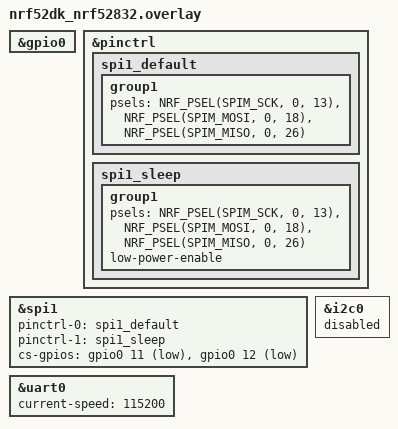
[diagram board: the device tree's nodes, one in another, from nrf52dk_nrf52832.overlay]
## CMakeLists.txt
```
# SPDX-License-Identifier: Apache-2.0

cmake_minimum_required(VERSION 3.20.0)

find_package(Zephyr REQUIRED HINTS $ENV{ZEPHYR_BASE})
project(ECG_Chestpatch)

target_sources(app PRIVATE src/main.c src/max30003.c src/lsm6dsm.c src/spi_config.c)
zephyr_library_include_directories(./include)

FILE(GLOB app_sources src/*.c)
target_sources(app PRIVATE
  ${app_sources}
  )

# zephyr_library_include_directories(${ZEPHYR_BASE}/samples/bluetooth)

# target_sources(app PRIVATE src/main.c src/max30003.c src/spi_config.c)
zephyr_library_include_directories(./include)
zephyr_library_include_directories(C:/ncs/v2.1.2/zephyr/include/) # Might only work on Vince's computer
```

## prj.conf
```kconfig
# nothing here
CONFIG_GPIO=y
CONFIG_SPI=y

CONFIG_SPI_ASYNC=y

CONFIG_SERIAL=y
CONFIG_UART_INTERRUPT_DRIVEN=y

CONFIG_SENSOR=y

CONFIG_NEWLIB_LIBC=y # Make sure to remove after debug to reduce image size?
CONFIG_NEWLIB_LIBC_FLOAT_PRINTF=y # Make sure to remove after debug to reduce image size?
# CONFIG_NEWLIB_LIBC=y # Make sure to remove after debug to reduce image size?
# CONFIG_NEWLIB_LIBC_FLOAT_PRINTF=y # Make sure to remove after debug to reduce image size?

CONFIG_BT=y
CONFIG_BT_DEBUG_LOG=y
CONFIG_BT_SMP=y
CONFIG_BT_PERIPHERAL=y
CONFIG_BT_DIS=y
CONFIG_BT_DIS_PNP=n
# CONFIG_BT_BAS=y
# CONFIG_BT_HRS=y
CONFIG_BT_DEVICE_NAME="Arthur"
CONFIG_BT_DEVICE_APPEARANCE=832
CONFIG_BT_BUF_ACL_RX_SIZE=251
CONFIG_BT_BUF_ACL_TX_SIZE=251
CONFIG_BT_L2CAP_TX_MTU=247
CONFIG_BT_CTLR_DATA_LENGTH_MAX=251
CONFIG_BT_USER_PHY_UPDATE=y
CONFIG_MAIN_STACK_SIZE=4096
```

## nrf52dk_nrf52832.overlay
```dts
// To get started, press Ctrl+Space to bring up the completion menu and view the available nodes.

// You can also use the buttons in the sidebar to perform actions on nodes.
// Actions currently available include:

// * Enabling / disabling the node
// * Adding the bus to a bus
// * Removing the node
// * Connecting ADC channels

// For more help, browse the DeviceTree documentation at https: //docs.zephyrproject.org/latest/guides/dts/index.html
// You can also visit the nRF DeviceTree extension documentation at https: //nrfconnect.github.io/vscode-nrf-connect/devicetree/nrfdevicetree.html

&gpio0 {
	status = "okay";
};

// This is where you specify which pin belongs to SCK, MOSI, and MISO. The pins need to be the same for spi1_default and spi1_sleep
&pinctrl {
	spi1_default: spi1_default {
		group1 {
			psels = <NRF_PSEL(SPIM_SCK, 0, 13)>,
				<NRF_PSEL(SPIM_MOSI, 0, 18)>,
				<NRF_PSEL(SPIM_MISO, 0, 26)>;
		};
	};

	spi1_sleep: spi1_sleep {
		group1 {
			psels = <NRF_PSEL(SPIM_SCK, 0, 13)>,
				<NRF_PSEL(SPIM_MOSI, 0, 18)>,
				<NRF_PSEL(SPIM_MISO, 0, 26)>;
			low-power-enable;
		};
	};
};


// It is CRITICAL to specify which pin belongs to cs-gpios here. Without it, the CS pins will not activate properly
&spi1 {
	status = "okay";
	pinctrl-0 = <&spi1_default>;
	pinctrl-1 = <&spi1_sleep>;
	pinctrl-names = "default", "sleep";
	cs-gpios = <&gpio0 11 GPIO_ACTIVE_LOW>,
				<&gpio0 12 GPIO_ACTIVE_LOW>;
};

&uart0 {
	current-speed = < 115200 >;
};

arduino_i2c: &i2c0 {
	status = "disabled";
};
```

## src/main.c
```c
/* main.c - Application main entry point */

/*
 * Copyright (c) 2015-2016 Intel Corporation
 *
 * SPDX-License-Identifier: Apache-2.0
 */

#include <zephyr/types.h>
#include <stddef.h>
#include <string.h>
#include <errno.h>
#include <zephyr/sys/printk.h>
#include <zephyr/sys/byteorder.h>
#include <zephyr/kernel.h>

#include <zephyr/bluetooth/bluetooth.h>
#include <zephyr/bluetooth/hci.h>
#include <zephyr/bluetooth/conn.h>
#include <zephyr/bluetooth/uuid.h>
#include <zephyr/bluetooth/gatt.h>

#include "ble_service.h"
#include "max30003.h"
#include "lsm6dsm.h"

#include <zephyr/drivers/gpio.h>

#define ECG_CHARACTERISTIC_STUFFING 30
#define ACCEL_CHARACTERISTIC_STUFFING 15 /*ENSURE IS MULTIPLE OF 3 (one for x, one for y, one for z)*/
#define GYRO_CHARACTERISTIC_STUFFING 15 /*ENSURE IS MULTIPLE OF 3 (one for x, one for y, one for z)*/

// Structure below is for setting up the Bluetooth connected LED
struct gpio_dt_spec led = 
	{
		.port = DEVICE_DT_GET(DT_NODELABEL(gpio0)),
		.pin = 20,
		.dt_flags = GPIO_ACTIVE_LOW
	};

static const struct bt_data ad[] = {
	BT_DATA_BYTES(BT_DATA_FLAGS, (BT_LE_AD_GENERAL | BT_LE_AD_NO_BREDR)),
	BT_DATA_BYTES(BT_DATA_UUID16_ALL,
		      BT_UUID_16_ENCODE(BT_UUID_DIS_VAL)),
};

// Current implementation of turning on the Bluetooth LED is weird. The board will start off with this LED on after being programmed.
static void connected(struct bt_conn *conn, uint8_t err)
{
	if (err) {
		printk("Connection failed (err 0x%02x)\n", err);
	} else {
		printk("Connected\n");
		gpio_pin_set_dt(&led, 1);
		bt_conn_le_phy_update(conn, BT_CONN_LE_PHY_PARAM_2M);
	}
}

static void disconnected(struct bt_conn *conn, uint8_t reason)
{
	printk("Disconnected (reason 0x%02x)\n", reason);
	gpio_pin_set_dt(&led, 0);
}

BT_CONN_CB_DEFINE(conn_callbacks) = {
	.connected = connected,
	.disconnected = disconnected,
};

static void bt_ready(void)
{
	int err;

	printk("Bluetooth initialized\n");

	err = bt_le_adv_start(BT_LE_ADV_CONN_NAME, ad, ARRAY_SIZE(ad), NULL, 0);
	if (err) {
		printk("Advertising failed to start (err %d)\n", err);
		return;
	}

	printk("Advertising successfully started\n");
}

static void auth_cancel(struct bt_conn *conn)
{
	char addr[BT_ADDR_LE_STR_LEN];

	bt_addr_le_to_str(bt_conn_get_dst(conn), addr, sizeof(addr));

	printk("Pairing cancelled: %s\n", addr);
}

static struct bt_conn_auth_cb auth_cb_display = {
	.cancel = auth_cancel,
};

// This function is just a wrapper for bt_ecg_notify.
static void ecg_notify(int32_t *ptr, uint8_t len)
{
	bt_ecg_notify(ptr, len);
}

// This function is just a wrapper for bt_accel_notify.
static void accel_notify(int16_t *ptr, uint8_t len)
{
	bt_accel_notify(ptr, len);
}

// This function is just a wrapper for bt_gyro_notify.
static void gyro_notify(int16_t *ptr, uint8_t len)
{
	bt_gyro_notify(ptr, len);
}

void main(void)
{
	int err;
	int ret;

	ret = gpio_pin_configure_dt(&led, GPIO_OUTPUT_ACTIVE);
	if (ret < 0) {
		return;
	}

	// Clears out any possible erroneous programming that may have occured on the peripherals
	lsm6dsm_reset_sw();
	max_reset_sw();

	lsm6dsm_enable_accel();
	lsm6dsm_enable_gyro();
	max_enable_ecg();

	err = bt_enable(NULL);
	if (err)
	{
		printk("Bluetooth init failed (err %d)\n", err);
		return;
	}

	bt_ready();

	bt_conn_auth_cb_register(&auth_cb_display);

	uint8_t lsm6dsm_status;

	int i = 0;
	int j = 0;
	int k = 0;

	int16_t accel_xyz[3] = {};
	int16_t gyro_xyz[3] = {};
	int32_t ecg_num;

	// Characteristic stuffing is when we load our data into an array and burst send it on Bluetooth. 
	// This is important as this reduces the number of times BLE has to notify and reduces the overhead associated with it.
	int32_t ecg_arr[ECG_CHARACTERISTIC_STUFFING];
	int16_t accel_arr[ACCEL_CHARACTERISTIC_STUFFING];
	int16_t gyro_arr[GYRO_CHARACTERISTIC_STUFFING];

	while (1) {
		ret = lsm6dsm_read_status(&lsm6dsm_status);
		// Checks to see if the LSM6DSM is ready to send out accelerometer data
		if (lsm6dsm_status & (1 << 0))
		{
			ret = lsm6dsm_read_accel(accel_xyz);
			if (!ret)
			{
				accel_arr[i] = accel_xyz[0];
				i += 1;
				accel_arr[i+1] = accel_xyz[1];
				i += 1;
				accel_arr[i+2] = accel_xyz[2];
				i += 1;
				if (i >= ACCEL_CHARACTERISTIC_STUFFING)
				{
					accel_notify(accel_arr, ACCEL_CHARACTERISTIC_STUFFING);
					i = 0;
				}
				// printf("Accel x: % 3.3f, y: % 3.3f, z: % 3.3f\n", ((float)accel_xyz[0]) * 0.061 / 1000 * 9.81, ((float)accel_xyz[1]) * 0.061 / 1000 * 9.81, ((float)accel_xyz[2]) * 0.061 / 1000 * 9.81);
			}
		}
		// Checks to see if the LSM6DSM is ready to send out gyroscope data
		if (lsm6dsm_status & (1 << 1))
		{
			ret = lsm6dsm_read_gyro(gyro_xyz);
			if (!ret)
			{
				gyro_arr[j] = gyro_xyz[0];
				j += 1;
				gyro_arr[j] = gyro_xyz[1];
				j += 1;
				gyro_arr[j] = gyro_xyz[2];
				j += 1;
				if (j >= GYRO_CHARACTERISTIC_STUFFING)
				{
					gyro_notify(gyro_arr, GYRO_CHARACTERISTIC_STUFFING);
					j=0;
				}
				// printf("Gyro x: % 3.3f, y: % 3.3f, z: % 3.3f\n", (gyro_xyz[0]) * 8.75 / 1000, (gyro_xyz[1]) * 8.75 / 1000, (gyro_xyz[2]) * 8.75 / 1000);
			}
		}
		ret = max_read_ecg(&ecg_num);
		if (!ret)
		{
			ecg_arr[k] = ecg_num;
			k++;
			// printk("%d\n", ecg_num);
			if (k >= ECG_CHARACTERISTIC_STUFFING)
			{
				ecg_notify(ecg_arr, ECG_CHARACTERISTIC_STUFFING);
				k = 0;
			}
		}
	}
}
```

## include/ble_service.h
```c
/*
 * Copyright (c) 2016 Intel Corporation
 *
 * SPDX-License-Identifier: Apache-2.0
 */

#ifndef ZEPHYR_INCLUDE_BLUETOOTH_SERVICES_HRS_H_
#define ZEPHYR_INCLUDE_BLUETOOTH_SERVICES_HRS_H_

/**
 * @brief Heart Rate Service (HRS)
 * @defgroup bt_hrs Heart Rate Service (HRS)
 * @ingroup bluetooth
 * @{
 *
 * [Experimental] Users should note that the APIs can change
 * as a part of ongoing development.
 */

#ifdef __cplusplus
extern "C" {
#endif

/** @brief Notify ecg measurement.
 *
 * This will send a GATT notification to all current subscribers.
 *
 *  @param ecg_val The ecg measurement as read from device.
 *
 *  @return Zero in case of success and error code in case of error.
 */
int bt_ecg_notify(int32_t *val, uint8_t len);
int bt_accel_notify(int16_t *ptr, uint8_t len);
// int bt_yaccel_notify(int16_t val);
// int bt_zaccel_notify(int16_t val);
int bt_gyro_notify(int16_t *ptr, uint8_t len);
// int bt_gyroy_notify(int16_t val);
// int bt_gyroz_notify(int16_t val);

#ifdef __cplusplus
}
#endif

/**
 * @}
 */

#endif /* ZEPHYR_INCLUDE_BLUETOOTH_SERVICES_HRS_H_ */
```

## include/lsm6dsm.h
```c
#include <stdio.h>
#include <zephyr/zephyr.h>

#ifndef LSM6DSM
#define LSM6DSM

#define BUF_SIZE 2

/*********** REGISTERS ***********/

/* Setup registers */
#define LSM6DSM_FUNC_CFG_ACCESS          (uint8_t)0x01U  /**< Enable embedded functions register (r/w) **/
#define LSM6DSM_SENSOR_SYNC_TIME_FRAME   (uint8_t)0x04U  /**< Sensor synchronization time frame register (r/w) **/
#define LSM6DSM_SENSOR_SYNC_RES_RATIO    (uint8_t)0x05U  /**< Sensor synchronization resolution ratio (r/w) **/

#define LSM6DSM_FIFO_CTRL1               (uint8_t)0x06U  /**< FIFO control register 1 (r/w) **/
#define LSM6DSM_FIFO_CTRL2               (uint8_t)0x07U  /**< FIFO control register 2 (r/w) **/
#define LSM6DSM_FIFO_CTRL3               (uint8_t)0x08U  /**< FIFO control register 3 (r/w) **/
#define LSM6DSM_FIFO_CTRL4               (uint8_t)0x09U  /**< FIFO control register 4 (r/w) **/
#define LSM6DSM_FIFO_CTRL5               (uint8_t)0x0AU  /**< FIFO control register 5 (r/w) **/

#define LSM6DSM_DRDY_PULSE_CFG_G         (uint8_t)0x0BU  /**< DataReady configuration register (r/w)**/
#define LSM6DSM_INT1_CTRL                (uint8_t)0x0DU  /**< INT1 pad control register (r/w) **/
#define LSM6DSM_INT2_CTRL                (uint8_t)0x0EU  /**< INT2 pad control register (r/w) **/

#define LSM6DSM_WHO_AM_I                 (uint8_t)0x0FU  /**< Who_AM_I register (r), value fixed at 6Ah **/

#define LSM6DSM_CTRL1_XL                 (uint8_t)0x10U  /**< Linear acceleration sensor control register 1 (r/w) **/
#define LSM6DSM_CTRL2_G                  (uint8_t)0x11U  /**< Angular rate sensor control register 2 (r/w) **/
#define LSM6DSM_CTRL3_C                  (uint8_t)0x12U  /**< Control register 3 (r/w) **/
#define LSM6DSM_CTRL4_C                  (uint8_t)0x13U  /**< Control register 4 (r/w) **/
#define LSM6DSM_CTRL5_C                  (uint8_t)0x14U  /**< Control register 5 (r/w) **/
#define LSM6DSM_CTRL6_C                  (uint8_t)0x15U  /**< Angular rate sensor control register 6 (r/w) **/
#define LSM6DSM_CTRL7_G                  (uint8_t)0x16U  /**< Angular rate sensor control register 7 (r/w) **/
#define LSM6DSM_CTRL8_XL                 (uint8_t)0x17U  /**< Linear acceleration sensor control register 8 (r/w) **/
#define LSM6DSM_CTRL9_XL                 (uint8_t)0x18U  /**< Linear acceleration sensor control register 9 (r/w) **/
#define LSM6DSM_CTRL10_C                 (uint8_t)0x19U  /**< Control register 10 (r/w) **/

#define LSM6DSM_MASTER_CONFIG            (uint8_t)0x1AU  /**< Master configuration register (r/w) **/
#define LSM6DSM_WAKE_UP_SRC              (uint8_t)0x1BU  /**< Wake up interrupt source register (r) **/
#define LSM6DSM_TAP_SRC                  (uint8_t)0x1CU  /**< Tap source register (r) **/
#define LSM6DSM_D6D_SRC                  (uint8_t)0x1DU  /**< Portrait, landscape, face-up and face-down source register (r) **/
#define LSM6DSM_STATUS_REG               (uint8_t)0x1EU  /**< Status register (r) **/


#define LSM6DSM_OUT_TEMP_L               (uint8_t)0x20U  /**< Temperature data output register Bit 7..0 (r) **/
#define LSM6DSM_OUT_TEMP_H               (uint8_t)0x21U  /**< Temperature data output register Bit 15..8 (r) **/


#define LSM6DSM_OUTX_L_G                 (uint8_t)0x22U  /**< Angular rate pitch axis X Bit 7..0 (r)**/
#define LSM6DSM_OUTX_H_G                 (uint8_t)0x23U  /**< Angular rate pitch axis X Bit 15..8 (r)**/
#define LSM6DSM_OUTY_L_G                 (uint8_t)0x24U  /**< Angular rate pitch axis Y Bit 7..0 (r)**/
#define LSM6DSM_OUTY_H_G                 (uint8_t)0x25U  /**< Angular rate pitch axis Y Bit 15..8 (r)**/
#define LSM6DSM_OUTZ_L_G                 (uint8_t)0x26U  /**< Angular rate pitch axis Z Bit 7..0 (r)**/
#define LSM6DSM_OUTZ_H_G                 (uint8_t)0x27U  /**< Angular rate pitch axis Z Bit 15..8 (r)**/

#define LSM6DSM_OUTX_L_XL                (uint8_t)0x28U  /**< Linear acceleration axis X Bit 7..0 (r)**/
#define LSM6DSM_OUTX_H_XL                (uint8_t)0x29U  /**< Linear acceleration axis X Bit 15..8 (r)**/
#define LSM6DSM_OUTY_L_XL                (uint8_t)0x2AU  /**< Linear acceleration axis Y Bit 7..0 (r)**/
#define LSM6DSM_OUTY_H_XL                (uint8_t)0x2BU  /**< Linear acceleration axis Y Bit 15..8 (r)**/
#define LSM6DSM_OUTZ_L_XL                (uint8_t)0x2CU  /**< Linear acceleration axis Z Bit 7..0 (r)**/
#define LSM6DSM_OUTZ_H_XL                (uint8_t)0x2DU  /**< Linear acceleration axis Z Bit 15..8 (r)**/

/** refer to @ref lsm6dsm_embedded_registers for following sensorhub bytes functionality **/
#define LSM6DSM_SENSORHUB1_REG           (uint8_t)0x2EU  /**< byte 1 associated to external sensors **/
#define LSM6DSM_SENSORHUB2_REG           (uint8_t)0x2FU  /**< byte 2 associated to external sensors **/
#define LSM6DSM_SENSORHUB3_REG           (uint8_t)0x30U  /**< byte 3 associated to external sensors **/
#define LSM6DSM_SENSORHUB4_REG           (uint8_t)0x31U  /**< byte 4 associated to external sensors **/
#define LSM6DSM_SENSORHUB5_REG           (uint8_t)0x32U  /**< byte 5 associated to external sensors **/
#define LSM6DSM_SENSORHUB6_REG           (uint8_t)0x33U  /**< byte 6 associated to external sensors **/
#define LSM6DSM_SENSORHUB7_REG           (uint8_t)0x34U  /**< byte 7 associated to external sensors **/
#define LSM6DSM_SENSORHUB8_REG           (uint8_t)0x35U  /**< byte 8 associated to external sensors **/
#define LSM6DSM_SENSORHUB9_REG           (uint8_t)0x36U  /**< byte 9 associated to external sensors **/
#define LSM6DSM_SENSORHUB10_REG          (uint8_t)0x37U  /**< byte 10 associated to external sensors **/
#define LSM6DSM_SENSORHUB11_REG          (uint8_t)0x38U  /**< byte 11 associated to external sensors **/ 
#define LSM6DSM_SENSORHUB12_REG          (uint8_t)0x39U  /**< byte 12 associated to external sensors **/

/** For a proper reading of the following registers, 
 *  it is recommended to set the BDU bit in CTRL3_C (12h) to 1 **/
#define LSM6DSM_FIFO_STATUS1             (uint8_t)0x3AU  /**< FIFO status control 1 (r) **/
#define LSM6DSM_FIFO_STATUS2             (uint8_t)0x3BU  /**< FIFO status control 2 (r)**/
#define LSM6DSM_FIFO_STATUS3             (uint8_t)0x3CU  /**< FIFO status control 3 (r)**/
#define LSM6DSM_FIFO_STATUS4             (uint8_t)0x3DU  /**< FIFO status control 4 (r) **/

#define LSM6DSM_FIFO_DATA_OUT_L          (uint8_t)0x3EU  /**< FIFO data output - Bit 7..0 (r)**/
#define LSM6DSM_FIFO_DATA_OUT_H          (uint8_t)0x3FU  /**< FIFO data output Bit - 15..8 (r)**/

/** to reset the Timestamp timer, (uint8_t)0xAA has to be written in TIMESTAMP2_REG **/
#define LSM6DSM_TIMESTAMP0_REG           (uint8_t)0x40U  /**< Timestamp data output - Bit 7..0 (r) **/
#define LSM6DSM_TIMESTAMP1_REG           (uint8_t)0x41U  /**< Timestamp data output - Bit 15..8 (r) **/
#define LSM6DSM_TIMESTAMP2_REG           (uint8_t)0x42U  /**< Timestamp data output - Bit 23..16 (r/w) **/
#define LSM6DSM_STEP_TIMESTAMP_L         (uint8_t)0x49U  /**< Step counter timestamp - contains TIMESTAMP0 (r)**/
#define LSM6DSM_STEP_TIMESTAMP_H         (uint8_t)0x4AU  /**< Step counter timestamp - contains TIMESTAMP1 (r)**/
#define LSM6DSM_STEP_COUNTER_L           (uint8_t)0x4BU  /**< Step counter output register - Bit 7..0 (r) **/
#define LSM6DSM_STEP_COUNTER_H           (uint8_t)0x4CU  /**< Step counter output register - Bit 13..8 (r) **/

#define LSM6DSM_SENSORHUB13_REG          (uint8_t)0x4DU  /**< byte 13 associated to external sensors **/
#define LSM6DSM_SENSORHUB14_REG          (uint8_t)0x4EU  /**< byte 14 associated to external sensors **/
#define LSM6DSM_SENSORHUB15_REG          (uint8_t)0x4FU  /**< byte 15 associated to external sensors **/
#define LSM6DSM_SENSORHUB16_REG          (uint8_t)0x50U  /**< byte 16 associated to external sensors **/
#define LSM6DSM_SENSORHUB17_REG          (uint8_t)0x51U  /**< byte 17 associated to external sensors **/
#define LSM6DSM_SENSORHUB18_REG          (uint8_t)0x52U  /**< byte 18 associated to external sensors **/
  
#define LSM6DSM_FUNC_SRC1                (uint8_t)0x53U  /**< Significant motion, tilt, step detector,   **/ 
                                                    /** hard/soft-iron and sensor hub interrupt source (r) **/
#define LSM6DSM_FUNC_SRC2                (uint8_t)0x54U  /**< Wrist tilt and slave NAK interrupt source (r) **/

#define LSM6DSM_WRIST_TILT_IA            (uint8_t)0x55U  /**< Wrist tilt interrupt source (r) **/
#define LSM6DSM_TAP_CFG                  (uint8_t)0x58U  /**< interrupt, inactivity function , filtering (r/w) **/
#define LSM6DSM_TAP_THS_6D               (uint8_t)0x59U  /**< Portrait/landscape, tap function threshold (r/w) **/
#define LSM6DSM_INT_DUR2                 (uint8_t)0x5AU  /**< Tap recognition function setting (r/w) **/
#define LSM6DSM_WAKE_UP_THS              (uint8_t)0x5BU  /**< Single and double-tap function threshold (r/w) **/
#define LSM6DSM_WAKE_UP_DUR              (uint8_t)0x5CU  /**< Free-fall, wakeup, timestamp, sleep duration (r/w) **/
#define LSM6DSM_FREE_FALL                (uint8_t)0x5DU  /**< Free-fall function duration setting register (r/w) **/
#define LSM6DSM_MD1_CFG                  (uint8_t)0x5EU  /**< Functions routing on INT1 register (r/w) **/
#define LSM6DSM_MD2_CFG                  (uint8_t)0x5FU  /**< Functions routing on INT2 register (r/w) **/

#define LSM6DSM_MASTER_CMD_CODE          (uint8_t)0x60U  /**< Master command code used for stamping **/
#define LSM6DSM_SENS_SYNC_SPI_ERROR_CODE (uint8_t)0x61U  /**< Error code used for sensor synchronization **/

#define LSM6DSM_OUT_MAG_RAW_X_L          (uint8_t)0x66U  /**< External magnetometer X data - Bit 7..0 (r) **/
#define LSM6DSM_OUT_MAG_RAW_X_H          (uint8_t)0x67U  /**< External magnetometer X data - Bit 15..8 (r) **/
#define LSM6DSM_OUT_MAG_RAW_Y_L          (uint8_t)0x68U  /**< External magnetometer Y data - Bit 7..0 (r) **/
#define LSM6DSM_OUT_MAG_RAW_Y_H          (uint8_t)0x69U  /**< External magnetometer Y data - Bit 15..8 (r) **/
#define LSM6DSM_OUT_MAG_RAW_Z_L          (uint8_t)0x6AU  /**< External magnetometer Z data - Bit 7..0 (r) **/
#define LSM6DSM_OUT_MAG_RAW_Z_H          (uint8_t)0x6BU  /**< External magnetometer Z data - Bit 15..8 (r) **/

#define LSM6DSM_INT_OIS                  (uint8_t)0x6FU  /**< OIS interrupt config (r) (AUX SPI (r/w)) **/
#define LSM6DSM_CTRL1_OIS                (uint8_t)0x70U  /**< OIS configuration 1 (r) (AUX SPI (r/w)) **/
#define LSM6DSM_CTRL2_OIS                (uint8_t)0x71U  /**< OIS configuration 2 (r) (AUX SPI (r/w)) **/
#define LSM6DSM_CTRL3_OIS                (uint8_t)0x72U  /**< OIS configuration 3 (r) (AUX SPI (r/w)) **/

#define LSM6DSM_X_OFS_USR                (uint8_t)0x73U  /**< Accelerometer X user offset correction (r/w) **/
#define LSM6DSM_Y_OFS_USR                (uint8_t)0x74U  /**< Accelerometer Y user offset correction (r/w) **/
#define LSM6DSM_Z_OFS_USR                (uint8_t)0x75U  /**< Accelerometer Z user offset correction (r/w) **/
/*! @} */

/*! @defgroup lsm6dsm_embedded_registers Group: embedded registers   
*  lsm6dsm embedded registers
*  @{
*/
#define LSM6DSM_SLV0_ADD                 (uint8_t)0x02U /**< I2C slave address Sensor   1 (r/w) **/
#define LSM6DSM_SLV0_SUBADD              (uint8_t)0x03U /**< Address of register Sensor 1 (r/w) **/
#define LSM6DSM_SLAVE0_CONFIG            (uint8_t)0x04U /**< configuration Sensor 1, sensor hub (r/w) **/
#define LSM6DSM_SLV1_ADD                 (uint8_t)0x05U /**< I2C slave address Sensor   2 (r/w) **/
#define LSM6DSM_SLV1_SUBADD              (uint8_t)0x06U /**< Address of register Sensor 2 (r/w) **/
#define LSM6DSM_SLAVE1_CONFIG            (uint8_t)0x07U /**< configuration Sensor       2 (r/w) **/
#define LSM6DSM_SLV2_ADD                 (uint8_t)0x08U /**< I2C slave address Sensor   3 (r/w) **/
#define LSM6DSM_SLV2_SUBADD              (uint8_t)0x09U /**< Address of register Sensor 3 (r/w) **/
#define LSM6DSM_SLAVE2_CONFIG            (uint8_t)0x0AU /**< configuration Sensor       3 (r/w) **/
#define LSM6DSM_SLV3_ADD                 (uint8_t)0x0BU /**< I2C slave address Sensor   4 (r/w) **/
#define LSM6DSM_SLV3_SUBADD              (uint8_t)0x0CU /**< Address of register Sensor 4 (r/w) **/
#define LSM6DSM_SLAVE3_CONFIG            (uint8_t)0x0DU /**< configuration Sensor       4 (r/w) **/

#define LSM6DSM_DATAWR_SRC_MODE_SUB_SLV0 (uint8_t)0x0EU /**< Write in SLV0 register  (r/w) **/
#define LSM6DSM_CONFIG_PEDO_THS_MIN      (uint8_t)0x0FU /**< Pedometer configuration (r/w) **/

#define LSM6DSM_SM_THS                   (uint8_t)0x13U /**< Significant motion configuration (r/w) **/
#define LSM6DSM_PEDO_DEB_REG             (uint8_t)0x14U /**< Pedometer debounce configuration (r/w) **/
#define LSM6DSM_STEP_COUNT_DELTA         (uint8_t)0x15U /**< Time period step detection  (r/w) **/

#define LSM6DSM_MAG_SI_XX                (uint8_t)0x24U /**< Soft-iron matrix correction row,col 1,1 (r/w)  **/
#define LSM6DSM_MAG_SI_XY                (uint8_t)0x25U /**< Soft-iron matrix correction row,col 1,2 (r/w)  **/
#define LSM6DSM_MAG_SI_XZ                (uint8_t)0x26U /**< Soft-iron matrix correction row,col 1,3 (r/w)  **/
#define LSM6DSM_MAG_SI_YX                (uint8_t)0x27U /**< Soft-iron matrix correction row,col 2,1 (r/w)  **/
#define LSM6DSM_MAG_SI_YY                (uint8_t)0x28U /**< Soft-iron matrix correction row,col 2,2 (r/w)  **/
#define LSM6DSM_MAG_SI_YZ                (uint8_t)0x29U /**< Soft-iron matrix correction row,col 2,3 (r/w)  **/
#define LSM6DSM_MAG_SI_ZX                (uint8_t)0x2AU /**< Soft-iron matrix correction row,col 3,1 (r/w)  **/
#define LSM6DSM_MAG_SI_ZY                (uint8_t)0x2BU /**< Soft-iron matrix correction row,col 3,2 (r/w)  **/
#define LSM6DSM_MAG_SI_ZZ                (uint8_t)0x2CU /**< Soft-iron matrix correction row,col 3,3 (r/w)  **/

#define LSM6DSM_MAG_OFFX_L               (uint8_t)0x2DU /**< Offset X-axis hard-iron compensation Bit 7..0 (r/w)**/
#define LSM6DSM_MAG_OFFX_H               (uint8_t)0x2EU /**< Offset X-axis hard-iron compensation Bit 15..8 (r/w)**/
#define LSM6DSM_MAG_OFFY_L               (uint8_t)0x2FU /**< Offset Y-axis hard-iron compensation Bit 7..0 (r/w)**/
#define LSM6DSM_MAG_OFFY_H               (uint8_t)0x30U /**< Offset Y-axis hard-iron compensation Bit 15..8 (r/w)**/
#define LSM6DSM_MAG_OFFZ_L               (uint8_t)0x31U /**< Offset Z-axis hard-iron compensation Bit 7..0 (r/w)**/
#define LSM6DSM_MAG_OFFZ_H               (uint8_t)0x32U /**< Offset Z-axis hard-iron compensation Bit 15..8 (r/w)**/

#define LSM6DSM_A_WRIST_TILT_LAT         (uint8_t)0x50U /**< Absolute Wrist Tilt latency (r/w) **/
#define LSM6DSM_A_WRIST_TILT_THS         (uint8_t)0x54U /**< Absolute Wrist Tilt threshold (r/w)**/
#define LSM6DSM_A_WRIST_TILT_MASK        (uint8_t)0x59U /**< Absolute Wrist Tilt mask (r/w)**/

/*! @} */

/*********** FUNCTIONS ***********/

bool lsm6dsm_read_who_am_i();

int lsm6dsm_enable_accel();
int lsm6dsm_write_buffer(uint8_t reg, uint8_t data);
int lsm6dsm_read_buffer(uint8_t reg, uint8_t *out_data);
int lsm6dsm_read_status(uint8_t *status_data);
int lsm6dsm_read_accel(int16_t *out_xyz);
int lsm6dsm_read_gyro(int16_t *out_xyz);

#endif // LSM6DSM
```

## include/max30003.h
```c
/*******************************************************************************
 * Copyright (C) 2017 Maxim Integrated Products, Inc., All Rights Reserved.
 *
 * Permission is hereby granted, free of charge, to any person obtaining a
 * copy of this software and associated documentation files (the "Software"),
 * to deal in the Software without restriction, including without limitation
 * the rights to use, copy, modify, merge, publish, distribute, sublicense,
 * and/or sell copies of the Software, and to permit persons to whom the
 * Software is furnished to do so, subject to the following conditions:
 *
 * The above copyright notice and this permission notice shall be included
 * in all copies or substantial portions of the Software.
 *
 * THE SOFTWARE IS PROVIDED "AS IS", WITHOUT WARRANTY OF ANY KIND, EXPRESS
 * OR IMPLIED, INCLUDING BUT NOT LIMITED TO THE WARRANTIES OF
 * MERCHANTABILITY, FITNESS FOR A PARTICULAR PURPOSE AND NONINFRINGEMENT.
 * IN NO EVENT SHALL MAXIM INTEGRATED BE LIABLE FOR ANY CLAIM, DAMAGES
 * OR OTHER LIABILITY, WHETHER IN AN ACTION OF CONTRACT, TORT OR OTHERWISE,
 * ARISING FROM, OUT OF OR IN CONNECTION WITH THE SOFTWARE OR THE USE OR
 * OTHER DEALINGS IN THE SOFTWARE.
 *
 * Except as contained in this notice, the name of Maxim Integrated
 * Products, Inc. shall not be used except as stated in the Maxim Integrated
 * Products, Inc. Branding Policy.
 *
 * The mere transfer of this software does not imply any licenses
 * of trade secrets, proprietary technology, copyrights, patents,
 * trademarks, maskwork rights, or any other form of intellectual
 * property whatsoever. Maxim Integrated Products, Inc. retains all
 * ownership rights.
 *******************************************************************************
 */

#ifndef _MAX30003_H_
#define _MAX30003_H_

// #include "mbed.h"
#include <string.h>
#include <stdio.h>
#include <zephyr/zephyr.h>

#include "spi_config.h"

#define MAX_BUF_SIZE 4

/**
 * @brief Library for MAX30003\n
 * The MAX30003 is a complete, biopotential, analog frontend solution for
 * wearable applications. It offers high performance for clinical and fitness
 * applications, with ultra-low power for long battery life. The MAX30003 is a
 * single biopotential channel providing ECG waveforms and heart rate detection.
 *
 * @code
 * #include "mbed.h"
 * #include "max32630fthr.h"
 * #include "MAX30003.h"
 *
 * MAX32630FTHR pegasus(MAX32630FTHR::VIO_3V3);
 *
 * int main(void)
 * {
 *     DigitalOut rLed(LED1, 1);
 *     DigitalOut gLed(LED2, 1);
 *
 *     Serial pc(USBTX, USBRX);
 *     pc.baud(115200);
 *
 *     SPI spiBus(SPI2_MOSI, SPI2_MISO, SPI2_SCK);
 *     MAX30003 ecgAfe(spiBus, P5_3);
 *
 *     while(1)
 *     {
 *         gLed = !gLed;
 *         wait(0.1);
 *     }
 * }
 * @endcode
 */

enum Registers_e
{
    NO_OP = 0x00,
    STATUS = 0x01,
    EN_INT = 0x02,
    EN_INT2 = 0x03,
    MNGR_INT = 0x04,
    MNGR_DYN = 0x05,
    SW_RST = 0x08,
    SYNCH = 0x09,
    FIFO_RST = 0x0A,
    INFO = 0x0F,
    CNFG_GEN = 0x10,
    CNFG_ALL = 0x12,
    CNFG_EMUX = 0x14,
    CNFG_ECG = 0x15,
    CNFG_RTOR1 = 0x1D,
    CNFG_RTOR2 = 0x1E,
    ECG_FIFO_BURST = 0x20,
    ECG_FIFO = 0x21,
    RTOR = 0x25,
    NO_OP2 = 0x7F
};

#define STATUS_LOFF_NL 0
#define STATUS_LOFF_NH 1
#define STATUS_LOFF_PL 2
#define STATUS_LOFF_PH 3
#define STATUS_PLLINT 8
#define STATUS_SAMP 9
#define STATUS_RRINT 10
#define STATUS_LONINT 11
#define STATUS_DCLOFFINT 20
#define STATUS_FSTINT 21
#define STATUS_EOVF 22
#define STATUS_EINT 23

#define EN_INT_INTB_TYPE 0
#define EN_INT_EN_PLLINT 8
#define EN_INT_EN_SAMP 9
#define EN_INT_EN_RRINT 10
#define EN_INT_EN_LONINT 11
#define EN_INT_EN_DCL_OFFINT 20
#define EN_INT_EN_FSTINT 21
#define EN_INT_EN_EOVF 22
#define EN_INT_EN_EINT 23

#define MNGR_INT_SAMP_IT 0
#define MNGR_INT_CLR_SAMP 2
#define MNGR_INT_CLR_RRINT 4
#define MNGR_INT_CLR_FAST 6
#define MNGR_INT_EFIT 19

#define MNGR_DYN_FAST_TH 16
#define MNGR_DYN_FAST 22

#define CNFG_GEN_RBIASN 0
#define CNFG_GEN_RBIASP 1
#define CNFG_GEN_RBIASV 2
#define CNFG_GEN_EN_RBIAS 4
#define CNFG_GEN_VTH 6
#define CNFG_GEN_IMAG 8
#define CNFG_GEN_IPOL 3
#define CNFG_GEN_EN_DCLOFF 12
#define CNFG_GEN_EN_ECG 19
#define CNFG_GEN_FMSTR 20
#define CNFG_GEN_EN_ULP_LON 22

#define CNFG_CAL_THIGH 0
#define CNFG_CAL_FIFTY 11
#define CNFG_CAL_FCAL 12
#define CNFG_CAL_VMAG 20
#define CNFG_CAL_VMODE 21
#define CNFG_CAL_EN_VCAL 22

#define CNFG_EMUX_CALN_SEL 16
#define CNFG_EMUX_CALP_SEL 18
#define CNFG_EMUX_OPENN 20
#define CNFG_EMUX_OPENP 21
#define CNFG_EMUX_POL 23

#define CNFG_ECG_DLPF 12
#define CNFG_ECG_DHPF 14
#define CNFG_ECG_GAIN 16
#define CNFG_ECG_RATE 22

#define CNFG_RTOR1_PTSF 8
#define CNFG_RTOR1_PAVG 12
#define CNFG_RTOR1_EN_RTOR 15
#define CNFG_RTOR1_GAIN 16
#define CNFG_RTOR1_WNDW 20

#define CNFG_RTOR2_RHSF 8
#define CNFG_RTOR2_RAVG 12
#define CNFG_RTOR2_HOFF 16

bool max_readinfo(void);

bool max_reset_sw(void);

int max_enable_ecg(void);

int max_readstatus(void);

int max_read_ecg(int32_t *out_val);

int max30003_write(uint8_t reg, void *data, size_t size);

int max30003_write_uint32(uint8_t reg, uint32_t data);

int max30003_read(uint8_t reg, void *data, size_t size);

#endif /* _MAX30003_H_ */
```

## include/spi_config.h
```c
#ifndef SPI_CONFIG
#define SPI_CONFIG

#include <zephyr/drivers/spi.h>

// CONFIGURATION STRUCTURES
extern struct spi_cs_control max_spi_cs;
extern struct spi_cs_control accel_spi_cs;

extern struct spi_config max_spi_cfg;
extern struct spi_config accel_spi_cfg;

// DEVICE POINTER
extern const struct device *spi_device;

#endif //SPI_CONFIG
```

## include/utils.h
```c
#ifndef UTILS
#define UTILS

#include <string.h>
#include <stdio.h>
#include <zephyr/zephyr.h>

static inline void to_display_format(const uint8_t *src, size_t size, char *dst)
{
	size_t i;

	for (i = 0; i < size; i++)
	{
		sprintf(dst + 5 * i, "0x%02x,", src[i]);
	}
}

#endif //UTILS
```

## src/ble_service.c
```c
/** @file
 *  @brief HRS Service sample
 */

/*
 * Copyright (c) 2016 Intel Corporation
 *
 * SPDX-License-Identifier: Apache-2.0
 */

#include <zephyr/types.h>
#include <stddef.h>
#include <string.h>
#include <errno.h>
#include <zephyr/zephyr.h>
#include <zephyr/init.h>

#include <zephyr/bluetooth/bluetooth.h>
#include <zephyr/bluetooth/hci.h>
#include <zephyr/bluetooth/conn.h>
#include <zephyr/bluetooth/uuid.h>
#include <zephyr/bluetooth/gatt.h>

#define LOG_LEVEL CONFIG_BT_HRS_LOG_LEVEL
#include <zephyr/logging/log.h>
LOG_MODULE_REGISTER(ecg);


#define GATT_PERM_READ_MASK     (BT_GATT_PERM_READ | \
				 BT_GATT_PERM_READ_ENCRYPT | \
				 BT_GATT_PERM_READ_AUTHEN)
#define GATT_PERM_WRITE_MASK    (BT_GATT_PERM_WRITE | \
				 BT_GATT_PERM_WRITE_ENCRYPT | \
				 BT_GATT_PERM_WRITE_AUTHEN)

#ifndef CONFIG_BT_HRS_DEFAULT_PERM_RW_AUTHEN
#define CONFIG_BT_HRS_DEFAULT_PERM_RW_AUTHEN 0
#endif
#ifndef CONFIG_BT_HRS_DEFAULT_PERM_RW_ENCRYPT
#define CONFIG_BT_HRS_DEFAULT_PERM_RW_ENCRYPT 0
#endif
#ifndef CONFIG_BT_HRS_DEFAULT_PERM_RW
#define CONFIG_BT_HRS_DEFAULT_PERM_RW 0
#endif

#define HRS_GATT_PERM_DEFAULT (						\
	CONFIG_BT_HRS_DEFAULT_PERM_RW_AUTHEN ?				\
	(BT_GATT_PERM_READ_AUTHEN | BT_GATT_PERM_WRITE_AUTHEN) :	\
	CONFIG_BT_HRS_DEFAULT_PERM_RW_ENCRYPT ?				\
	(BT_GATT_PERM_READ_ENCRYPT | BT_GATT_PERM_WRITE_ENCRYPT) :	\
	(BT_GATT_PERM_READ | BT_GATT_PERM_WRITE))			\

// Custom service UUID
#define BT_UUID_ECG_SERVICE_VAL BT_UUID_128_ENCODE(0xed6c43b9, 0xb481, 0x4735, 0xad3a, 0x182d050c3688) //ed6c43b9-b481-4735-ad3a-182d050c3688
#define BT_UUID_ECG_SERVICE BT_UUID_DECLARE_128(BT_UUID_ECG_SERVICE_VAL)

// Custom ECG characteristic UUID
#define BT_ECG_CHRC_VAL BT_UUID_128_ENCODE(0x60a19d0d, 0x7e6c, 0x4d6a, 0xac49, 0x9b3c29a0ca94) //60a19d0d-7e6c-4d6a-ac49-9b3c29a0ca94
#define BT_ECG_CHRC BT_UUID_DECLARE_128(BT_ECG_CHRC_VAL)

// Custom accelerometer service UUID
#define BT_UUID_ACCELEROMETER_SERVICE_VAL1 BT_UUID_128_ENCODE(0xb35a0ebb, 0x4f41, 0x41b0, 0x8d70, 0x96b4dc15d9e7) //b35a0ebb-4f41-41b0-8d70-96b4dc15d9e7
#define BT_UUID_ACCELEROMETER_SERVICE1 BT_UUID_DECLARE_128(BT_UUID_ACCELEROMETER_SERVICE_VAL1)

// Custom accelerometer x characteristic UUID
#define BT_XACCEL_CHRC_VAL BT_UUID_128_ENCODE(0x3b8cdf21, 0x24a2, 0x468c, 0x9236, 0x20f50b770bf5) //3b8cdf21-24a2-468c-9236-20f50b770bf5
#define BT_XACCEL_CHRC BT_UUID_DECLARE_128(BT_XACCEL_CHRC_VAL)

// Custom accelerometer y characteristic UUID
#define BT_YACCEL_CHRC_VAL BT_UUID_128_ENCODE(0x1094b4ef, 0x76bd, 0x4341, 0xaa96, 0x83f99198db63) //1094b4ef-76bd-4341-aa96-83f99198db63
#define BT_YACCEL_CHRC BT_UUID_DECLARE_128(BT_YACCEL_CHRC_VAL)

// Custom accelerometer z characteristic UUID
#define BT_ZACCEL_CHRC_VAL BT_UUID_128_ENCODE(0xf5f4e4fe, 0x1ab0, 0x4aea, 0x9334, 0xb19fc27d6e7c) //f5f4e4fe-1ab0-4aea-9334-b19fc27d6e7c
#define BT_ZACCEL_CHRC BT_UUID_DECLARE_128(BT_ZACCEL_CHRC_VAL)

// Custom accelerometer gyro characteristic UUID
#define BT_GYRO_CHRC_VAL BT_UUID_128_ENCODE(0xff3675ff, 0x5479, 0x4e1c, 0x9d87, 0xa0ac6e2dadbf) //ff3675ff-5479-4e1c-9d87-a0ac6e2dadbf
#define BT_GYRO_CHRC BT_UUID_DECLARE_128(BT_GYRO_CHRC_VAL)

#define BT_GYROY_CHRC_VAL BT_UUID_128_ENCODE(0xc040eb24, 0x7174, 0x4f86, 0xa547, 0x659b538d9c31) // c040eb24-7174-4f86-a547-659b538d9c31
#define BT_GYROY_CHRC BT_UUID_DECLARE_128(BT_GYROY_CHRC_VAL)

#define BT_GYROZ_CHRC_VAL BT_UUID_128_ENCODE(0x4f30dd9e, 0x9c7c, 0x48d5, 0xb071, 0xd1924af65ac6) // 4f30dd9e-9c7c-48d5-b071-d1924af65ac6
#define BT_GYROZ_CHRC BT_UUID_DECLARE_128(BT_GYROZ_CHRC_VAL)

static int32_t ecg_reading;
static int16_t accelx_reading;
static int16_t accely_reading;
static int16_t accelz_reading;
static int16_t gyro_reading;
static int16_t gyroy_reading;
static int16_t gyroz_reading;

static void ecg_ccc_cfg_changed(const struct bt_gatt_attr *attr, int16_t value)
{
	ARG_UNUSED(attr);

	bool notif_enabled = (value == BT_GATT_CCC_NOTIFY);

	LOG_INF("notifications %s", notif_enabled ? "enabled" : "disabled");
}

static void xaccel_ccc_cfg_changed(const struct bt_gatt_attr *attr, int16_t value)
{
	ARG_UNUSED(attr);

	bool notif_enabled = (value == BT_GATT_CCC_NOTIFY);

	LOG_INF("notifications %s", notif_enabled ? "enabled" : "disabled");
}

static void yaccel_ccc_cfg_changed(const struct bt_gatt_attr *attr, int16_t value)
{
	ARG_UNUSED(attr);

	bool notif_enabled = (value == BT_GATT_CCC_NOTIFY);

	LOG_INF("notifications %s", notif_enabled ? "enabled" : "disabled");
}

static void zaccel_ccc_cfg_changed(const struct bt_gatt_attr *attr, int16_t value)
{
	ARG_UNUSED(attr);

	bool notif_enabled = (value == BT_GATT_CCC_NOTIFY);

	LOG_INF("notifications %s", notif_enabled ? "enabled" : "disabled");
}

static void gyro_ccc_cfg_changed(const struct bt_gatt_attr *attr, int16_t value)
{
	ARG_UNUSED(attr);

	bool notif_enabled = (value == BT_GATT_CCC_NOTIFY);

	LOG_INF("notifications %s", notif_enabled ? "enabled" : "disabled");
}

static void gyroy_ccc_cfg_changed(const struct bt_gatt_attr *attr, int16_t value)
{
	ARG_UNUSED(attr);

	bool notif_enabled = (value == BT_GATT_CCC_NOTIFY);

	LOG_INF("notifications %s", notif_enabled ? "enabled" : "disabled");
}

static void gyroz_ccc_cfg_changed(const struct bt_gatt_attr *attr, int16_t value)
{
	ARG_UNUSED(attr);

	bool notif_enabled = (value == BT_GATT_CCC_NOTIFY);

	LOG_INF("notifications %s", notif_enabled ? "enabled" : "disabled");
}


/* ECG Service Declaration */
BT_GATT_SERVICE_DEFINE(ecg_svc,
	BT_GATT_PRIMARY_SERVICE(BT_UUID_ECG_SERVICE),
	BT_GATT_CHARACTERISTIC(BT_ECG_CHRC, BT_GATT_CHRC_NOTIFY,
			       BT_GATT_PERM_NONE, NULL, NULL, NULL),
	BT_GATT_CCC(ecg_ccc_cfg_changed,
		    HRS_GATT_PERM_DEFAULT),
);

/* Accelerometer Service Declaration */
BT_GATT_SERVICE_DEFINE(accelerometer_svc,
	BT_GATT_PRIMARY_SERVICE(BT_UUID_ACCELEROMETER_SERVICE1),
	BT_GATT_CHARACTERISTIC(BT_XACCEL_CHRC, BT_GATT_CHRC_NOTIFY,
			       BT_GATT_PERM_NONE, NULL, NULL, NULL),
	BT_GATT_CCC(xaccel_ccc_cfg_changed,
		    HRS_GATT_PERM_DEFAULT),
	BT_GATT_CHARACTERISTIC(BT_YACCEL_CHRC, BT_GATT_CHRC_NOTIFY,
			       BT_GATT_PERM_NONE, NULL, NULL, NULL),
	BT_GATT_CCC(yaccel_ccc_cfg_changed,
		    HRS_GATT_PERM_DEFAULT),
	BT_GATT_CHARACTERISTIC(BT_ZACCEL_CHRC, BT_GATT_CHRC_NOTIFY,
				BT_GATT_PERM_NONE, NULL, NULL, NULL),
	BT_GATT_CCC(zaccel_ccc_cfg_changed,
		    HRS_GATT_PERM_DEFAULT),
	BT_GATT_CHARACTERISTIC(BT_GYRO_CHRC, BT_GATT_CHRC_NOTIFY,
				BT_GATT_PERM_NONE, NULL, NULL, NULL),
	BT_GATT_CCC(gyro_ccc_cfg_changed,
		    HRS_GATT_PERM_DEFAULT),
	BT_GATT_CHARACTERISTIC(BT_GYROY_CHRC, BT_GATT_CHRC_NOTIFY,
				BT_GATT_PERM_NONE, NULL, NULL, NULL),
	BT_GATT_CCC(gyroy_ccc_cfg_changed,
		    HRS_GATT_PERM_DEFAULT),
	BT_GATT_CHARACTERISTIC(BT_GYROZ_CHRC, BT_GATT_CHRC_NOTIFY,
				BT_GATT_PERM_NONE, NULL, NULL, NULL),
	BT_GATT_CCC(gyroz_ccc_cfg_changed,
		    HRS_GATT_PERM_DEFAULT),
	
);

static int chestpatch_val_init(const struct device *dev)
{
	ARG_UNUSED(dev);

	ecg_reading = 0x00;
	accelx_reading = 0x00;
	accely_reading = 0x00;
	accelz_reading = 0x00;
	gyro_reading = 0x00;
	gyroy_reading = 0x00;
	gyroz_reading = 0x00;
	return 0;
}

int bt_ecg_notify(int32_t *val, uint8_t len)
{
	int rc;

	rc = bt_gatt_notify(NULL, &ecg_svc.attrs[2], val, len*sizeof(*val));

	return rc == -ENOTCONN ? 0 : rc;
}

int bt_accel_notify(int16_t *ptr, uint8_t len)
{
	int rc;

	rc = bt_gatt_notify(NULL, &accelerometer_svc.attrs[2], ptr, len*sizeof(*ptr));

	return rc == -ENOTCONN ? 0 : rc;
}

// int bt_yaccel_notify(int16_t val)
// {
// 	int rc;
// 	static int16_t yaccel;

// 	yaccel = val;

// 	rc = bt_gatt_notify(NULL, &accelerometer_svc.attrs[5], &yaccel, sizeof(yaccel));

// 	return rc == -ENOTCONN ? 0 : rc;
// }

// int bt_zaccel_notify(int16_t val)
// {
// 	int rc;
// 	static int16_t zaccel;

// 	zaccel = val;

// 	rc = bt_gatt_notify(NULL, &accelerometer_svc.attrs[8], &zaccel, sizeof(zaccel));

// 	return rc == -ENOTCONN ? 0 : rc;
// }

int bt_gyro_notify(int16_t *ptr, uint8_t len)
{
	int rc;
	
	rc = bt_gatt_notify(NULL, &accelerometer_svc.attrs[11], ptr, len*sizeof(*ptr));

	return rc == -ENOTCONN ? 0 : rc;
}

// int bt_gyroy_notify(int16_t val)
// {
// 	int rc;
// 	static int16_t gyroy;

// 	gyroy = val;

// 	rc = bt_gatt_notify(NULL, &accelerometer_svc.attrs[14], &gyroy, sizeof(gyroy));

// 	return rc == -ENOTCONN ? 0 : rc;
// }

// int bt_gyroz_notify(int16_t val)
// {
// 	int rc;
// 	static int16_t gyroz;

// 	gyroz = val;

// 	rc = bt_gatt_notify(NULL, &accelerometer_svc.attrs[17], &gyroz, sizeof(gyroz));

// 	return rc == -ENOTCONN ? 0 : rc;
// }

SYS_INIT(chestpatch_val_init, APPLICATION, CONFIG_APPLICATION_INIT_PRIORITY);
```

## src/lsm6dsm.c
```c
#include <string.h>
#include <stdio.h>
#include <zephyr/zephyr.h>

#include "utils.h"
#include "spi_config.h"
#include "lsm6dsm.h"


#define WRITE_BIT_SET(reg) (reg & ~(1 << 7))
#define READ_BIT_SET(reg) (reg | (1 << 7))


uint8_t buffer_tx[BUF_SIZE] = {0x00, 0x00};
uint8_t buffer_rx[BUF_SIZE] = {0x00, 0x00};

uint8_t buffer_print_tx[BUF_SIZE * 5 + 1];
uint8_t buffer_print_rx[BUF_SIZE * 5 + 1];

struct spi_buf tx_bufs[1] = {
	{
		.buf = buffer_tx,
		.len = BUF_SIZE
	}
};

struct spi_buf rx_bufs[1] = 
{
	{
		.buf = buffer_rx,
		.len = BUF_SIZE
	}
};
const struct spi_buf_set tx = {
	.buffers = tx_bufs,
	.count = ARRAY_SIZE(tx_bufs)
};
const struct spi_buf_set rx = {
	.buffers = rx_bufs,
	.count = ARRAY_SIZE(rx_bufs)
};

// Verifies successful wiring/SPI configuration.
bool lsm6dsm_read_who_am_i()
{
    uint8_t who_am_i = 0;
	lsm6dsm_read_buffer(LSM6DSM_WHO_AM_I, &who_am_i);
	if (who_am_i == 0x6a)
	{
		printk("Accelerometer WHO_AM_I successful!\n");
		return true;
	} else 
	{
		printk("Accelerometer WHO_AM_I failed!\n");
		return false;
	}

}

int lsm6dsm_write_buffer(uint8_t reg, uint8_t data)
{
    uint8_t reg_write = WRITE_BIT_SET(reg);
    buffer_tx[0] = reg_write;
    buffer_tx[1] = data;
    return spi_transceive(spi_device, &accel_spi_cfg, &tx, NULL);
}

int lsm6dsm_read_buffer(uint8_t reg, uint8_t *out_data)
{
    buffer_tx[0] = READ_BIT_SET(reg);
    int ret = spi_transceive(spi_device, &accel_spi_cfg, &tx, &rx);
    *out_data = buffer_rx[1];

    return ret;
}

int lsm6dsm_enable_accel()
{
	int ret;
	ret = lsm6dsm_write_buffer(LSM6DSM_CTRL1_XL, 0x10); // Enable accelerometer to produce an output data rate of 12.5 Hz
	if (!ret)
	{
		return -1;
	}
	return 0;
}

int lsm6dsm_enable_gyro()
{
	int ret;
	ret = lsm6dsm_write_buffer(LSM6DSM_CTRL2_G, 0x10); // Enable gyrometer to produce an output data rate of 12.5 Hz
	if (!ret)
	{
		return -1;
	}
	return 0;
}

int lsm6dsm_read_status(uint8_t *status_data)
{
	int ret;
	ret = lsm6dsm_read_buffer(LSM6DSM_STATUS_REG, status_data);
	return ret;
}

int lsm6dsm_reset_sw(void)
{
	int ret = lsm6dsm_write_buffer(LSM6DSM_CTRL3_C, 0x01);
	return ret;
}

int lsm6dsm_read_accel(int16_t *out_xyz)
{
	uint8_t out_var = 0;
	uint8_t outx_xl[2] = {}; // element 0 is LSB, element 1 is MSB
	uint8_t outy_xl[2] = {};
	uint8_t outz_xl[2] = {};
	lsm6dsm_read_buffer(LSM6DSM_STATUS_REG, &out_var);
	if (out_var & (1<<0))
	{
		lsm6dsm_read_buffer(LSM6DSM_OUTX_L_XL, &outx_xl[0]);
		lsm6dsm_read_buffer(LSM6DSM_OUTX_H_XL, &outx_xl[1]);
		lsm6dsm_read_buffer(LSM6DSM_OUTY_L_XL, &outy_xl[0]);
		lsm6dsm_read_buffer(LSM6DSM_OUTY_H_XL, &outy_xl[1]);
		lsm6dsm_read_buffer(LSM6DSM_OUTZ_L_XL, &outz_xl[0]);
		lsm6dsm_read_buffer(LSM6DSM_OUTZ_H_XL, &outz_xl[1]);
		int16_t raw_outx_xl = outx_xl[0] | (outx_xl[1] << 8);
		if (!(raw_outx_xl < 32768))
		{
			raw_outx_xl -= 65536;
		}
		int16_t raw_outy_xl = outy_xl[0] | (outy_xl[1] << 8);
		if (!(raw_outy_xl < 32768))
		{
			raw_outy_xl -= 65536;
		}
		int16_t raw_outz_xl = outz_xl[0] | (outz_xl[1] << 8);
		if (!(raw_outz_xl < 32768))
		{
			raw_outz_xl -= 65536;
		}
		/*
		0.061 is the conversion factor between signed bits and mili-gravity. It is defined in pg 23 of the  datasheet
		1/1000 is the converstion from mili to base
		9.81 is the converstion from gravity to m/s^2
		*/
		out_xyz[0] = (raw_outx_xl); //*0.061/1000*9.81
		out_xyz[1] = (raw_outy_xl);
		out_xyz[2] = (raw_outz_xl);
	}
	else
	{
		return 1;
	};
	return 0;
}

int lsm6dsm_read_gyro(int16_t *out_xyz)
{
	int ret;
	uint8_t out_var = 0;
	uint8_t outx_g[2] = {}; // element 0 is LSB, element 1 is MSB
	uint8_t outy_g[2] = {};
	uint8_t outz_g[2] = {};
	{
		ret = lsm6dsm_read_buffer(LSM6DSM_OUTX_L_G, &outx_g[0]);
		ret = lsm6dsm_read_buffer(LSM6DSM_OUTX_H_G, &outx_g[1]);
		ret = lsm6dsm_read_buffer(LSM6DSM_OUTY_L_G, &outy_g[0]);
		ret = lsm6dsm_read_buffer(LSM6DSM_OUTY_H_G, &outy_g[1]);
		ret = lsm6dsm_read_buffer(LSM6DSM_OUTZ_L_G, &outz_g[0]);
		ret = lsm6dsm_read_buffer(LSM6DSM_OUTZ_H_G, &outz_g[1]);
		int16_t raw_outx_g = outx_g[0] | (outx_g[1] << 8);
		if (!(raw_outx_g < 32768))
		{
			raw_outx_g -= 65536;
		}
		int16_t raw_outy_g = outy_g[0] | (outy_g[1] << 8);
		if (!(raw_outy_g < 32768))
		{
			raw_outy_g -= 65536;
		}
		int16_t raw_outz_g = outz_g[0] | (outz_g[1] << 8);
		if (!(raw_outz_g < 32768))
		{
			raw_outz_g -= 65536;
		}
		/*
		8.75 is the conversion factor between signed bits and degrees-per-second. It is defined in 
		pg 23 of the datasheet. 1/1000 is the converstion from mili to base.
		*/
		out_xyz[0] = (raw_outx_g); //*8.75/1000
		out_xyz[1] = (raw_outy_g);
		out_xyz[2] = (raw_outz_g);
	}
	return ret;
}
```

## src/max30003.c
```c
#include <zephyr/device.h>
#include <zephyr/drivers/gpio.h>
#include <zephyr/drivers/spi.h>
#include "utils.h"
#include "spi_config.h"

#include "max30003.h"

#define WRITE_REG(reg) ((reg << 1) & ~(1 << 0))
#define READ_REG(reg) ((reg << 1) | (1 << 0))

uint8_t max_buffer_tx[MAX_BUF_SIZE] = {};
uint8_t max_buffer_rx[MAX_BUF_SIZE] = {};

// Debug print buffers for printing out hex values to terminal.
uint8_t max_buffer_print_tx[MAX_BUF_SIZE * 5 + 1];
uint8_t max_buffer_print_rx[MAX_BUF_SIZE * 5 + 1];

/*Number inside the [] Tells us how many buffers*/
/*.buf is the type of buffer*/
/*.len is the length of the buffer*/
struct spi_buf max_tx_bufs[2] = {};

struct spi_buf max_rx_bufs[2] = {};

const struct spi_buf_set max_tx = 
{
	.buffers = max_tx_bufs,
	.count = ARRAY_SIZE(max_tx_bufs)
};

const struct spi_buf_set max_rx = 
{
	.buffers = max_rx_bufs,
	.count = ARRAY_SIZE(max_rx_bufs)
};

/**
* @brief Reading a register of the MAX
* @param reg The register to be read
* @param data Array containing the information of the register
* @param size The size of the input data
*
* @retval 0 if successful
* @retval 1 if failed
*/
int max30003_read(uint8_t reg, void *data, size_t size)
{
	reg = READ_REG(reg);
	uint8_t dummy;
	max_tx_bufs[0].buf = &reg;
	max_tx_bufs[0].len = 1;
	max_tx_bufs[1].buf = NULL;
	max_tx_bufs[1].len = 0;
	max_rx_bufs[0].buf = &dummy;
	max_rx_bufs[0].len = 1;
	max_rx_bufs[1].buf = data;
	max_rx_bufs[1].len = size;

	int ret = spi_transceive(spi_device, &max_spi_cfg, &max_tx, &max_rx);
	return ret;
}

/**
* @brief Writting a register of the MAX
* @param reg The register to be written
* @param Array containing the information to be written
* @param size The size of the input data
*
* @retval 0 if successful
* @retval 1 if failed
*/
int max30003_write(uint8_t reg, void *data, size_t size)
{   
	reg = WRITE_REG(reg);
	max_tx_bufs[0].buf = &reg;
	max_tx_bufs[0].len = 1;
	max_tx_bufs[1].buf = data;
	max_tx_bufs[1].len = size;
	int ret = spi_transceive(spi_device, &max_spi_cfg, &max_tx, NULL);
	return ret;
}

int max30003_write_uint32(uint8_t reg, uint32_t data)
{   
	reg = WRITE_REG(reg);

	uint8_t write_out[3] = {(data >> 16) &(0xff), (data >> 8) &(0xff), (data >> 0) &(0xff)};
	//uint8_t write_out[3] = {(data >> 0) &(0xff), (data >> 8) &(0xff), (data >> 16) &(0xff)};
	max_tx_bufs[0].buf = &reg;
	max_tx_bufs[0].len = 1;
	max_tx_bufs[1].buf = write_out;
	max_tx_bufs[1].len = 3;
	int ret = spi_transceive(spi_device, &max_spi_cfg, &max_tx, NULL);
	if (ret != 0)
	{
		printk("Error spi writing!\n");
	}
	return ret;
}

/**
* @brief Software reset, equivalent to power-cycling the device
* 
* @retval Returns 0 after operation is done
*/
bool max_reset_sw()
{
	int ret;
	ret = max30003_write_uint32(SW_RST, 0);
	return 0;
}

/**
* @brief Reads the INFO (0x0F) register
*
* @retval Returns true if the device is read
* @retval Returns false if the device is not read
*/
bool max_readinfo()
{
	uint8_t data[3];

	int ret = max30003_read(INFO, data, sizeof data);
	// to_display_format(data, 3, max_buffer_print_rx);
	// printk("Receiving: %s\n", max_buffer_print_rx);
	// printk("spi_transcieve returns %d \n", ret);

	if ((data[0] & 0xF0) == 0x50)
	{
		printk("MAX is ready!\n");
		printk("Dev ID: ");
		printk("%x \n", data[0] & 0xFF);
		return true;
	}
	else
	{
		printk("MAX read info error! Check wiring!\n");
		return false;
	}
}

/**
 * @brief Reads STATUS (0x01) 
 * 
 * @retval 3 Byte Array of the contents of the STATUS register
 */
int max_readstatus()
{
	uint8_t data[3];
	int ret = max30003_read(STATUS, data, sizeof data);
	to_display_format(data, 3, max_buffer_print_rx);
	printk("Status Register: %s\n", max_buffer_print_rx);

	if(ret != 0)
	{
		printk("Read status failed!\n");
		return -1;
	}

	return ret;
}

// The pin configurations were taken from Maxim Integrated's demo code repository. See the link below and scroll down to the bottom of main.c
// https://os.mbed.com/teams/MH/code/MAX30003WING_monitorhealth_beta_test1_Ch//file/8fc65c8fa0e8/main.cpp/
int max_enable_ecg()
{
	int ret;

	uint32_t cnfg_gen_reg = (1 << CNFG_GEN_EN_ECG) | (0 << CNFG_GEN_RBIASN) | (1 << CNFG_GEN_RBIASP) | (1 << CNFG_GEN_EN_RBIAS)
								| (2 << CNFG_GEN_IMAG) | (1 << CNFG_GEN_EN_DCLOFF);
	ret = max30003_write_uint32(CNFG_GEN, cnfg_gen_reg);

    uint32_t cnfg_ecg_reg = (0b10 << CNFG_ECG_DLPF) | (1 << CNFG_ECG_DHPF) | (0b11 << CNFG_ECG_GAIN) | (0b10 << CNFG_ECG_RATE);
	ret = max30003_write_uint32(CNFG_ECG, cnfg_ecg_reg);

    uint32_t cnfg_rtor_reg = (0b0011 << CNFG_RTOR1_WNDW) | (0b1111 << CNFG_RTOR1_GAIN) | (0b11 << CNFG_RTOR1_PAVG) 
								| (0b0011 << CNFG_RTOR1_PTSF) | (1 << CNFG_RTOR1_EN_RTOR);
    ret = max30003_write_uint32(CNFG_RTOR1, cnfg_rtor_reg);

	// Registry involved with setting up interrupts
    // uint32_t mngr_int_reg = (0b00011 << MNGR_INT_EFIT) | (0b01 << MNGR_INT_CLR_RRINT);
	// ret = max30003_write_uint32(MNGR_INT, mngr_int_reg);

	// uint32_t en_int_reg = (1 << EN_INT_EN_EINT) | (1 << EN_INT_EN_RRINT) | (0b11 << EN_INT_INTB_TYPE);
	// ret = max30003_write_uint32(EN_INT, en_int_reg);

	uint32_t mngr_dyn_reg = 0x00000000 & ~(1 << MNGR_DYN_FAST);
	ret = max30003_write_uint32(MNGR_DYN, mngr_dyn_reg);

	uint32_t cnfg_emux_reg = 0x00000000 & ~(1 << CNFG_EMUX_OPENN) & ~(1 << CNFG_EMUX_OPENP);
	ret = max30003_write_uint32(CNFG_EMUX, cnfg_emux_reg);

	ret = max30003_write_uint32(SYNCH, 0x00000000);
	ret = max30003_write_uint32(FIFO_RST, 0x00000000);

	return ret;
}

int max_read_ecg(int32_t *out_val)
{
	int ret;
	uint8_t data[3] = {0x00, 0x00, 0x00};
	ret = max30003_read(STATUS, data, sizeof(data));
	// Checks to see if FIFO register has overflowed. If so, reset FIFO register.
	if (data[0] & (1 << 6))
	{
		printk("OVERFLOW!\n");
		ret = max30003_write_uint32(FIFO_RST, 0x00000000);
		return 1;
	}

	// Checks to see if FIFO register is ready to be read.
	if (data[0] & (1 << 7))
	{
		ret = max30003_read(ECG_FIFO, data, sizeof(data));
		uint32_t ecg_data = ((data[0] << 16) | (data[1] << 8) | (data[2] << 0)) >> 6;
		uint8_t data_tags = ((data[2] & (0x3F)) >> 3);

		// Checks to see if the data read is good.
		if (data_tags != 0)
		{
			return 1;
		}
		// Returned data is in two's complement, converting it to signed int32.
		if (ecg_data > 131072)
		{
			*out_val = ecg_data - 262144;
		} else
		{
			*out_val = ecg_data;
		}
		return 0;
	}
	else
	{
		return 1;
	}
}
```
